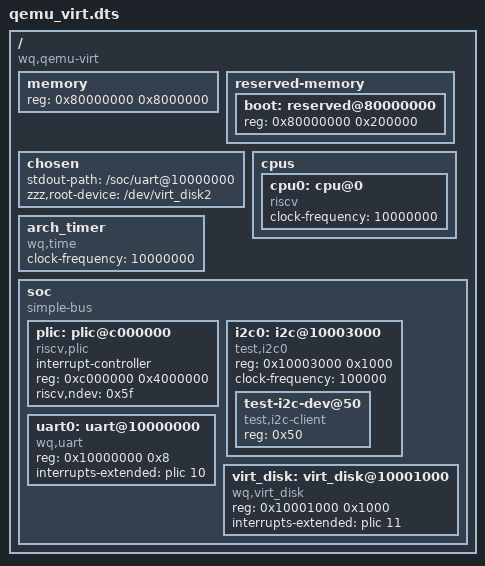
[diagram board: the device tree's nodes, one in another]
/dts-v1/;
/ {
    #address-cells = <1>;
    #size-cells = <1>;
    compatible = "wq,qemu-virt";

    memory {
        device_type = "memory";
        reg = < 0x80000000 0x8000000>; 
    };

    reserved-memory {
        #address-cells = <1>;
        #size-cells = <1>;
        ranges;
        boot: reserved@80000000 {
            reg = <0x80000000 0x200000>; // 保留内存区域
        };
    };

    chosen {
        stdout-path = "/soc/uart@10000000";
        zzz,root-device = "/dev/virt_disk2";
    };

    cpus {
        // compatible = "riscv";
        #address-cells = <1>;
        #size-cells = <1>;
        cpu0: cpu@0 {
            compatible = "riscv";
            device_type = "cpu";
            clock-frequency = <10000000>;
        };
    };

    arch_timer {
        compatible = "wq,time";
        clock-frequency = <10000000>;
    };

    soc {
        #address-cells = <1>;
        #size-cells = <1>;
        compatible = "simple-bus";

        plic: plic@c000000 {
            compatible = "riscv,plic";
            interrupt-controller;
            reg = <0xc000000 0x4000000>;
            #interrupt-cells = <1>;
            riscv,ndev = <0x5f>;
        };

        i2c0: i2c@10003000 {
            compatible = "test,i2c0";
            reg = <0x10003000 0x1000>;
            #address-cells = <1>;      // 子节点地址用 1 个 cell（7-bit 地址）
            #size-cells = <0>;          // 子节点不用 reg 表示长度
            clock-frequency = <100000>; // 100kHz

            test-i2c-dev@50 {
                compatible = "test,i2c-client";
                reg = <0x50>;
            };
        };
       
        // time: time@50000000 {
        //     compatible = "wq,time";
        //     reg = <0x50000000 0x1c>;
        // };
  
        uart0: uart@10000000 {
            compatible = "wq,uart";
            reg = <0x10000000 0x8>;
            interrupts-extended = <&plic 10>;
        };

        virt_disk: virt_disk@10001000 {
            compatible = "wq,virt_disk";
            reg = <0x10001000 0x1000>;
            interrupts-extended = <&plic 11>;
        };

    };
};
